# R9A02G021 register map
Vendor: Renesas Electronics Corporation; Series: RISC-V; File version: 1.10.00 + 202304131714_CPU
CPU: other r0p0, little endian, no MPU, no FPU, VTOR, 4 interrupt priority bits, 32 interrupts
Registers are 8-bit, read-write, reset 0x0 unless marked. A register's access mark holds for its fields unless they carry their own. Offsets are from the block's base; [hi:lo] are bit positions; {n}, {i} and the like mark numbered series; 'fields as' and 'values as' point back to an identical list.

## PFS — Pmn Pin Function Control Register
Base 0x40040800
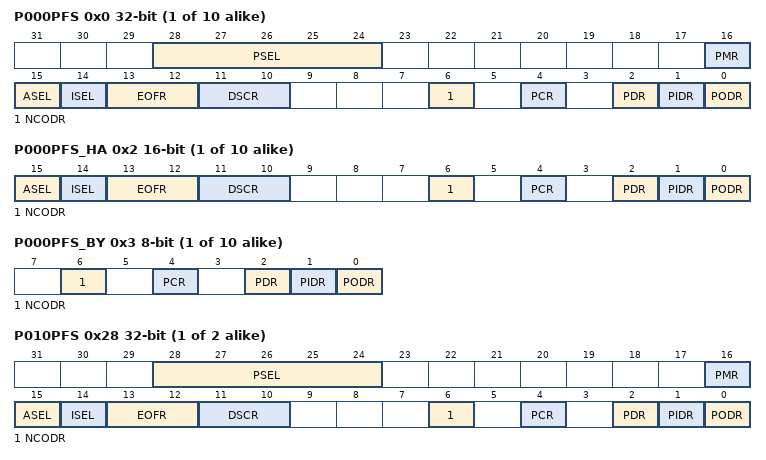
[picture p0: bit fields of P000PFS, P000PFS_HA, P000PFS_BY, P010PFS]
{0x0+4i} P00{i}PFS (i=0..9) 32-bit (reset mask 0xFFFFFFFD) — Port 00{i} Pin Function Select Register
  [28:24] PSEL — Peripheral Select
  [16] PMR — Port Mode Control
    0=Used as a general I/O pin; 1=Used as an I/O port for peripheral functions
  [15] ASEL — Analog Input Enable
    0=Not used as an analog pin; 1=Used as an analog pin
  [14] ISEL — IRQ Input Enable
    0=Not used as an IRQn input pin; 1=Used as an IRQn input pin
  [13:12] EOFR — Event on Falling (EOF)/Event on Rising (EOR)
    0=Don't care; 1=Detect rising edge; 2=Detect falling edge; 3=Detect both edges
  [11:10] DSCR — Port Output Current Control
    0=2 mA; 1=5 mA; 0b1x=10 mA
  [6] NCODR — N-Channel Open-Drain Control
    0=CMOS output; 1=NMOS open-drain output
  [4] PCR — Pull-up Control
    0=Disable input pull-up; 1=Enable input pull-up
  [2] PDR — Port Direction
    0=Input (functions as an input pin); 1=Output (functions as an output pin)
  [1] PIDR ro — Pmn State
    0=Low level; 1=High level
  [0] PODR — Port Output Data
    0=Low output; 1=High output
{0x2+4i} P00{i}PFS_HA (i=0..9) 16-bit (reset mask 0xFFFD) (alternate view of P00{i}PFS) — Port 00{i} Pin Function Select Register
  [15] ASEL — Analog Input Enable
    0=Not used as an analog pin; 1=Used as an analog pin
  [14] ISEL — IRQ Input Enable
    0=Not used as an IRQn input pin; 1=Used as an IRQn input pin
  [13:12] EOFR — Event on Falling (EOF)/Event on Rising (EOR)
    values as P000PFS.EOFR
  [11:10] DSCR — Port Output Current Control
    0=2 mA; 1=5 mA; 0b1x=10 mA
  [6] NCODR — N-Channel Open-Drain Control
    0=CMOS output; 1=NMOS open-drain output
  [4] PCR — Pull-up Control
    0=Disable input pull-up; 1=Enable input pull-up
  [2] PDR — Port Direction
    values as P000PFS.PDR
  [1] PIDR ro — Pmn State
    0=Low level; 1=High level
  [0] PODR — Port Output Data
    0=Low output; 1=High output
{0x3+4i} P00{i}PFS_BY (i=0..9) (reset mask 0xFD) (alternate view of P00{i}PFS) — Port 00{i} Pin Function Select Register
  [6] NCODR — N-Channel Open-Drain Control
    0=CMOS output; 1=NMOS open-drain output
  [4] PCR — Pull-up Control
    0=Disable input pull-up; 1=Enable input pull-up
  [2] PDR — Port Direction
    values as P000PFS.PDR
  [1] PIDR ro — Pmn State
    0=Low level; 1=High level
  [0] PODR — Port Output Data
    0=Low output; 1=High output
{0x0+4i} P0{i}PFS (i=10..11) 32-bit (reset mask 0xFFFFFFFD) — Port 0{i} Pin Function Select Register
  fields as P000PFS
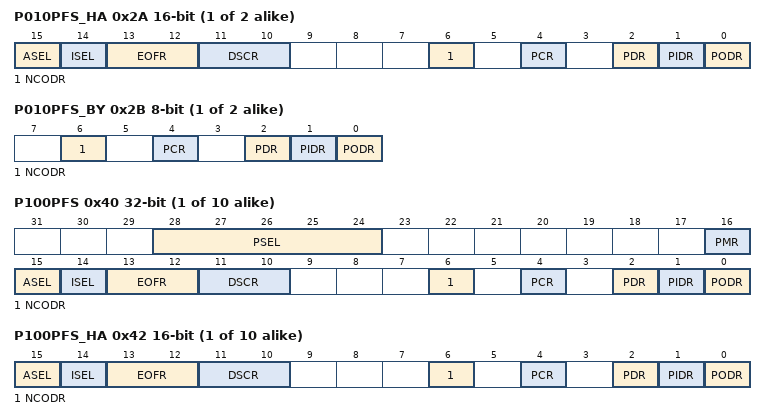
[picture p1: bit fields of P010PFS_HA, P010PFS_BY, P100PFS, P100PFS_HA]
{0x2+4i} P0{i}PFS_HA (i=10..11) 16-bit (reset mask 0xFFFD) (alternate view of P0{i}PFS) — Port 0{i} Pin Function Select Register
  fields as P000PFS_HA
{0x3+4i} P0{i}PFS_BY (i=10..11) (reset mask 0xFD) (alternate view of P0{i}PFS) — Port 0{i} Pin Function Select Register
  fields as P000PFS_BY
{0x40+4i} P10{i}PFS (i=0..9) 32-bit (reset mask 0xFFFFFFFD) — Port 10{i} Pin Function Select Register
  fields as P000PFS
{0x42+4i} P10{i}PFS_HA (i=0..9) 16-bit (reset mask 0xFFFD) (alternate view of P10{i}PFS) — Port 10{i} Pin Function Select Register
  fields as P000PFS_HA
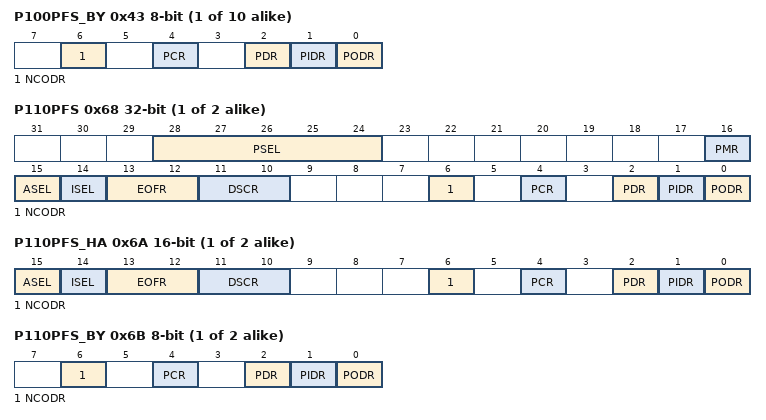
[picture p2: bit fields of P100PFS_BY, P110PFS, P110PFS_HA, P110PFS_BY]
{0x43+4i} P10{i}PFS_BY (i=0..9) (reset mask 0xFD) (alternate view of P10{i}PFS) — Port 10{i} Pin Function Select Register
  fields as P000PFS_BY
{0x40+4i} P1{i}PFS (i=10..11) 32-bit (reset mask 0xFFFFFFFD) — Port 1{i} Pin Function Select Register
  fields as P000PFS
{0x42+4i} P1{i}PFS_HA (i=10..11) 16-bit (reset mask 0xFFFD) (alternate view of P1{i}PFS) — Port 1{i} Pin Function Select Register
  fields as P000PFS_HA
{0x43+4i} P1{i}PFS_BY (i=10..11) (reset mask 0xFD) (alternate view of P1{i}PFS) — Port 1{i} Pin Function Select Register
  fields as P000PFS_BY
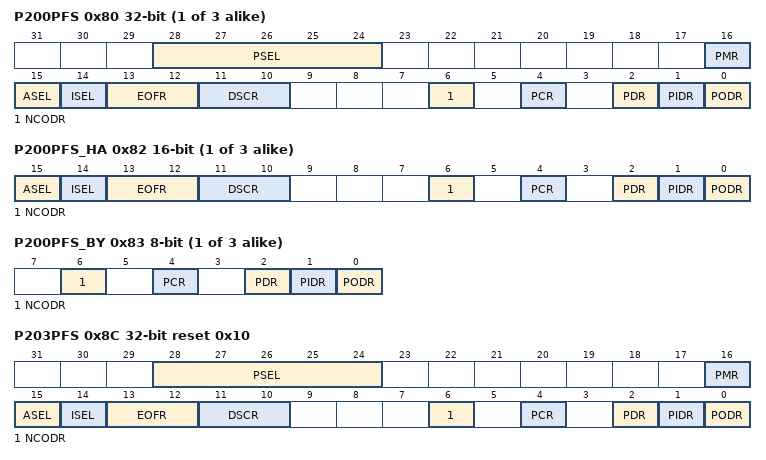
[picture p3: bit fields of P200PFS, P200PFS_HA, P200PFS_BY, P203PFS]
{0x80+4i} P20{i}PFS (i=0..2) 32-bit (reset mask 0xFFFFFFFD) — Port 20{i} Pin Function Select Register
  fields as P000PFS
{0x82+4i} P20{i}PFS_HA (i=0..2) 16-bit (reset mask 0xFFFD) (alternate view of P20{i}PFS) — Port 20{i} Pin Function Select Register
  fields as P000PFS_HA
{0x83+4i} P20{i}PFS_BY (i=0..2) (reset mask 0xFD) (alternate view of P20{i}PFS) — Port 20{i} Pin Function Select Register
  fields as P000PFS_BY
0x8C P203PFS 32-bit reset 0x10 (reset mask 0xFFFFFFFD) — Port 203 Pin Function Select Register
  fields as P000PFS
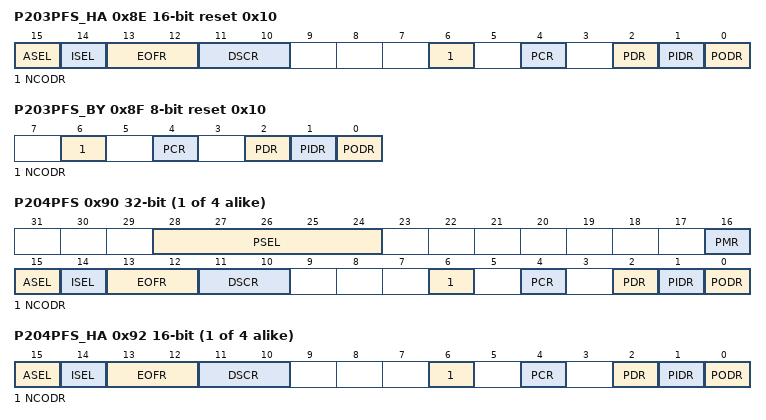
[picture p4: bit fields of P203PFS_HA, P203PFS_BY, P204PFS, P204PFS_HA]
0x8E P203PFS_HA 16-bit reset 0x10 (reset mask 0xFFFD) (alternate view of P203PFS) — Port 203 Pin Function Select Register
  fields as P000PFS_HA
0x8F P203PFS_BY reset 0x10 (reset mask 0xFD) (alternate view of P203PFS) — Port 203 Pin Function Select Register
  fields as P000PFS_BY
{0x80+4i} P20{i}PFS (i=4..7) 32-bit (reset mask 0xFFFFFFFD) — Port 20{i} Pin Function Select Register
  fields as P000PFS
{0x82+4i} P20{i}PFS_HA (i=4..7) 16-bit (reset mask 0xFFFD) (alternate view of P20{i}PFS) — Port 20{i} Pin Function Select Register
  fields as P000PFS_HA
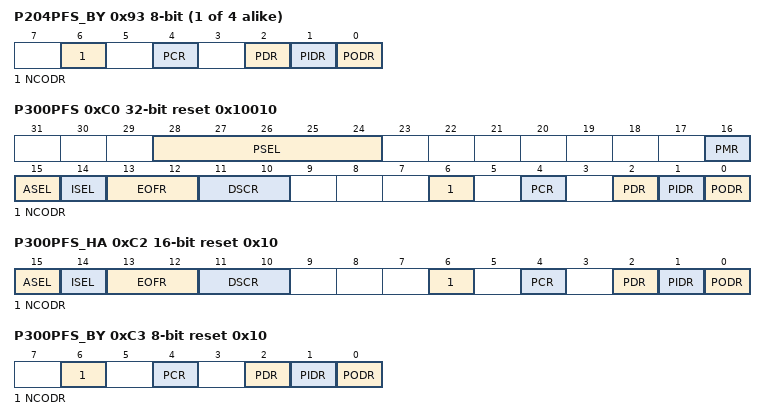
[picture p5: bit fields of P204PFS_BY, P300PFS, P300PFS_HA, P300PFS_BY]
{0x83+4i} P20{i}PFS_BY (i=4..7) (reset mask 0xFD) (alternate view of P20{i}PFS) — Port 20{i} Pin Function Select Register
  fields as P000PFS_BY
0xC0 P300PFS 32-bit reset 0x10010 (reset mask 0xFFFFFFFD) — Port 300 Pin Function Select Register
  fields as P000PFS
0xC2 P300PFS_HA 16-bit reset 0x10 (reset mask 0xFFFD) (alternate view of P300PFS) — Port 300 Pin Function Select Register
  fields as P000PFS_HA
0xC3 P300PFS_BY reset 0x10 (reset mask 0xFD) (alternate view of P300PFS) — Port 300 Pin Function Select Register
  fields as P000PFS_BY
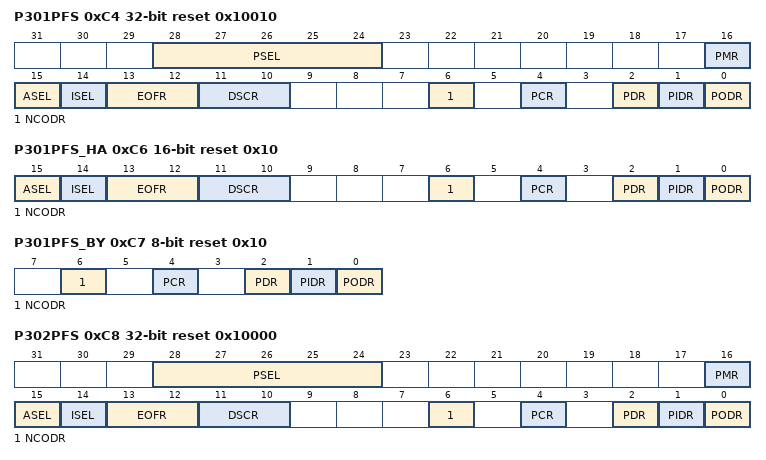
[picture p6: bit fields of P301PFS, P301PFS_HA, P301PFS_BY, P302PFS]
0xC4 P301PFS 32-bit reset 0x10010 (reset mask 0xFFFFFFFD) — Port 301 Pin Function Select Register
  fields as P000PFS
0xC6 P301PFS_HA 16-bit reset 0x10 (reset mask 0xFFFD) (alternate view of P301PFS) — Port 301 Pin Function Select Register
  fields as P000PFS_HA
0xC7 P301PFS_BY reset 0x10 (reset mask 0xFD) (alternate view of P301PFS) — Port 301 Pin Function Select Register
  fields as P000PFS_BY
0xC8 P302PFS 32-bit reset 0x10000 (reset mask 0xFFFFFFFD) — Port 302 Pin Function Select Register
  fields as P000PFS
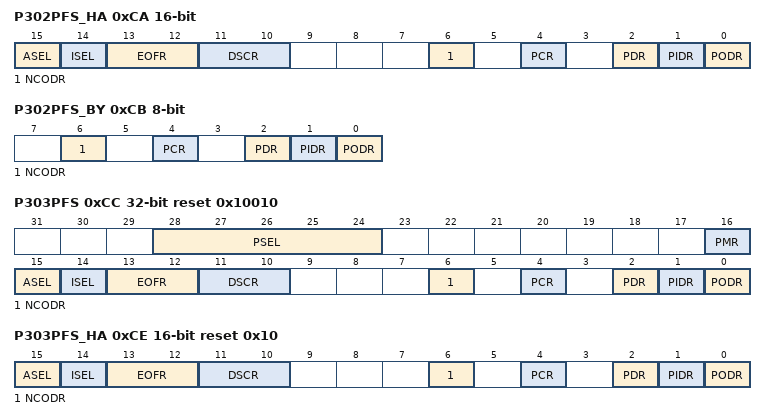
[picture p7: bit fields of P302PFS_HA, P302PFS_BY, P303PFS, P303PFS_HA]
0xCA P302PFS_HA 16-bit (reset mask 0xFFFD) (alternate view of P302PFS) — Port 302 Pin Function Select Register
  fields as P000PFS_HA
0xCB P302PFS_BY (reset mask 0xFD) (alternate view of P302PFS) — Port 302 Pin Function Select Register
  fields as P000PFS_BY
0xCC P303PFS 32-bit reset 0x10010 (reset mask 0xFFFFFFFD) — Port 303 Pin Function Select Register
  fields as P000PFS
0xCE P303PFS_HA 16-bit reset 0x10 (reset mask 0xFFFD) (alternate view of P303PFS) — Port 303 Pin Function Select Register
  fields as P000PFS_HA
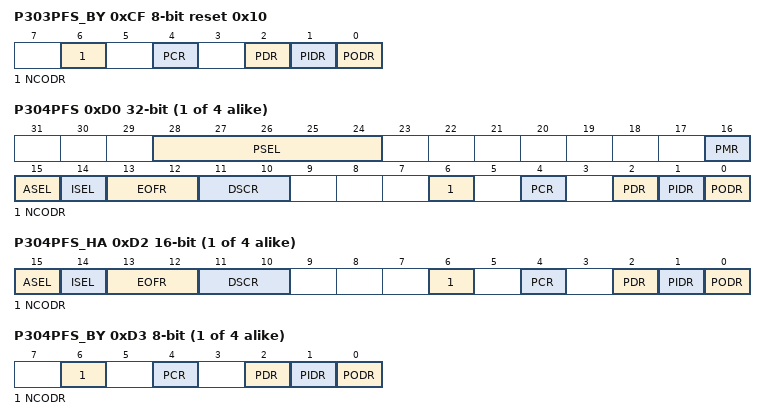
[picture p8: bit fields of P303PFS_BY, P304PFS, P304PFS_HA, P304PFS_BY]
0xCF P303PFS_BY reset 0x10 (reset mask 0xFD) (alternate view of P303PFS) — Port 303 Pin Function Select Register
  fields as P000PFS_BY
{0xC0+4i} P30{i}PFS (i=4..7) 32-bit (reset mask 0xFFFFFFFD) — Port 30{i} Pin Function Select Register
  fields as P000PFS
{0xC2+4i} P30{i}PFS_HA (i=4..7) 16-bit (reset mask 0xFFFD) (alternate view of P30{i}PFS) — Port 30{i} Pin Function Select Register
  fields as P000PFS_HA
{0xC3+4i} P30{i}PFS_BY (i=4..7) (reset mask 0xFD) (alternate view of P30{i}PFS) — Port 30{i} Pin Function Select Register
  fields as P000PFS_BY
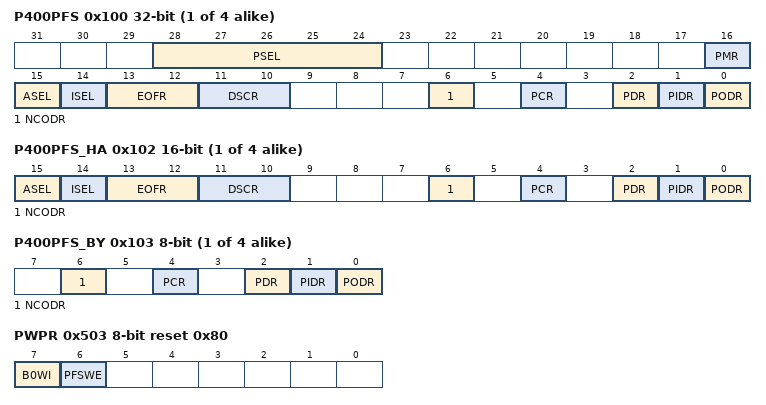
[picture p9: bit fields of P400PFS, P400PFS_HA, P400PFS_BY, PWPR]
{0x100+4i} P40{i}PFS (i=0..3) 32-bit (reset mask 0xFFFFFFFD) — Port 40{i} Pin Function Select Register
  fields as P000PFS
{0x102+4i} P40{i}PFS_HA (i=0..3) 16-bit (reset mask 0xFFFD) (alternate view of P40{i}PFS) — Port 40{i} Pin Function Select Register
  fields as P000PFS_HA
{0x103+4i} P40{i}PFS_BY (i=0..3) (reset mask 0xFD) (alternate view of P40{i}PFS) — Port 40{i} Pin Function Select Register
  fields as P000PFS_BY
0x503 PWPR reset 0x80 — Write-Protect Register
  [7] B0WI — PFSWE Bit Write Disable
    0=Writing to the PFSWE bit is enabled; 1=Writing to the PFSWE bit is disabled
  [6] PFSWE — PmnPFS Register Write Enable
    0=Writing to the PmnPFS register is disabled; 1=Writing to the PmnPFS register is enabled
0x50F PRWCNTR wo reset 0x1 — Port Read Wait Control Register
  [1:0] WAIT — Wait Cycle Control
    0=Setting prohibited; 1=Insert a 1-cycle wait; 2=Insert a 2-cycle wait; 3=Insert a 3-cycle wait
